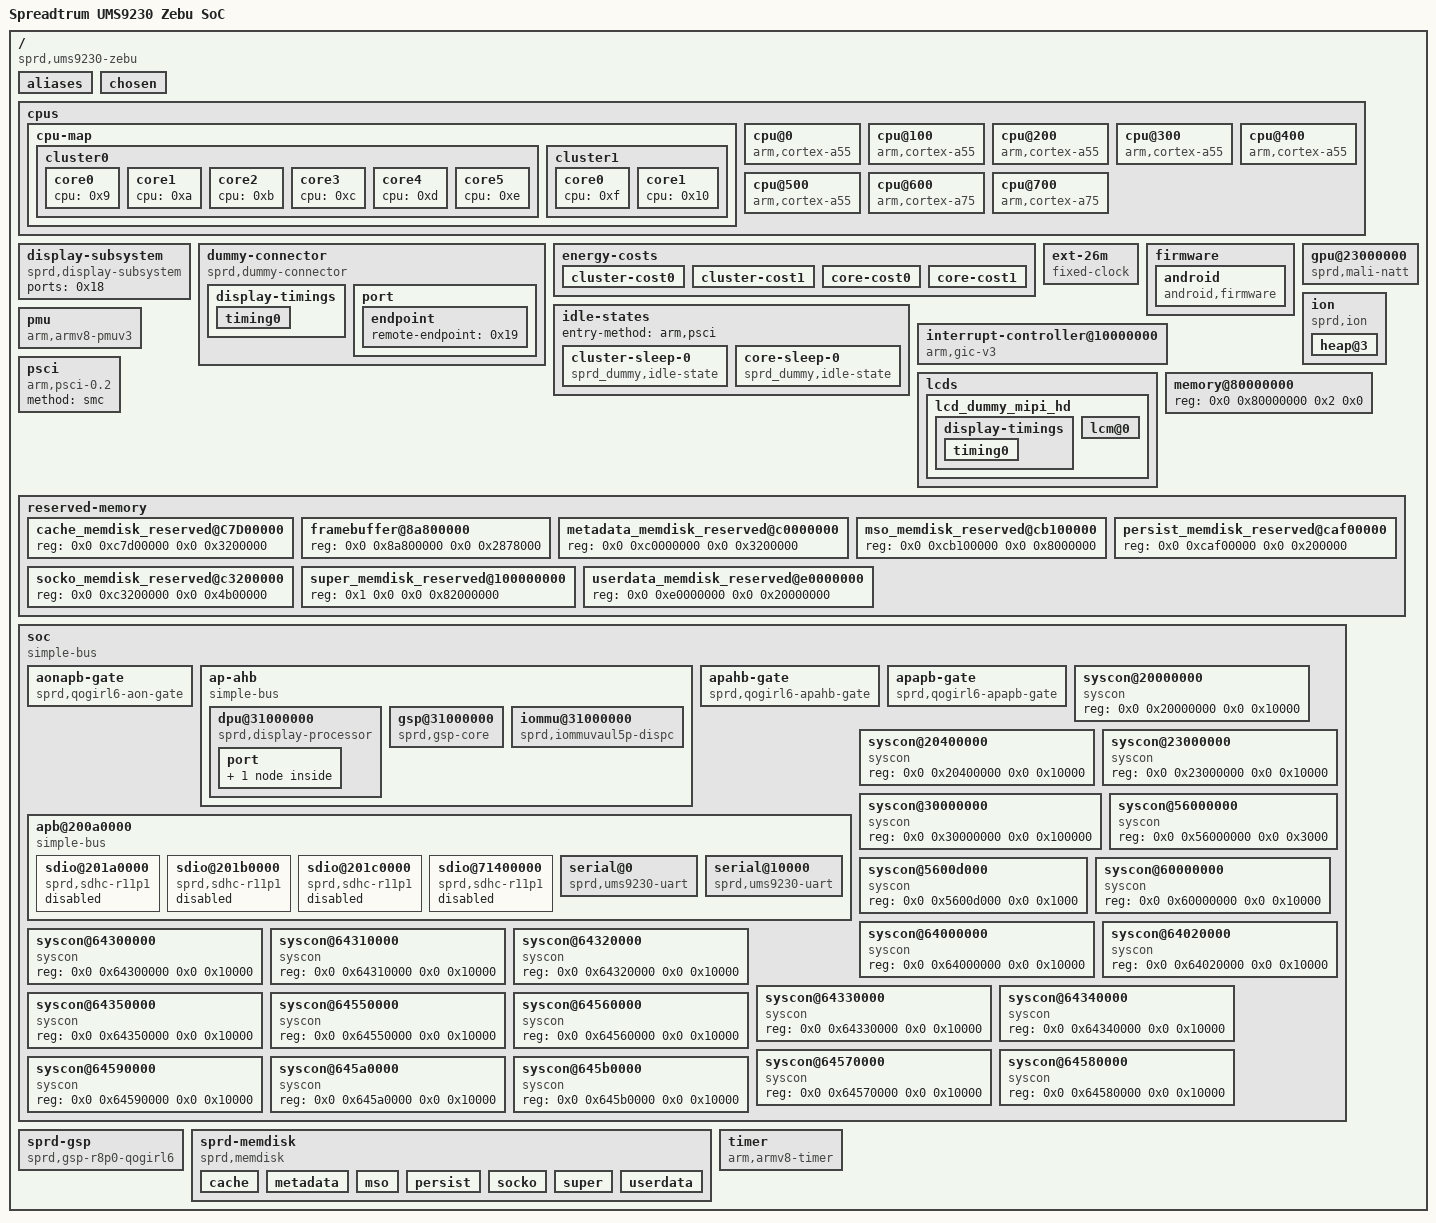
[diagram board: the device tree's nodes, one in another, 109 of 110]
/dts-v1/;

/ {
	#address-cells = <0x2>;
	#size-cells = <0x2>;
	compatible = "sprd,ums9230-zebu";
	interrupt-parent = <0x1>;
	model = "Spreadtrum UMS9230 Zebu SoC";
	sprd,sc-id = "ums9230-zebu 1000 1000";

	__symbols__ {
		CLUSTER_COST_0 = "/energy-costs/cluster-cost0";
		CLUSTER_COST_1 = "/energy-costs/cluster-cost1";
		CLUSTER_SLEEP_0 = "/idle-states/cluster-sleep-0";
		CORE_SLEEP_0 = "/idle-states/core-sleep-0";
		CPU0 = "/cpus/cpu@0";
		CPU1 = "/cpus/cpu@100";
		CPU2 = "/cpus/cpu@200";
		CPU3 = "/cpus/cpu@300";
		CPU4 = "/cpus/cpu@400";
		CPU5 = "/cpus/cpu@500";
		CPU6 = "/cpus/cpu@600";
		CPU7 = "/cpus/cpu@700";
		CPU_COST_0 = "/energy-costs/core-cost0";
		CPU_COST_1 = "/energy-costs/core-cost1";
		anlg_phy_g0_regs = "/soc/syscon@64550000";
		anlg_phy_g10_regs = "/soc/syscon@645b0000";
		anlg_phy_g1_regs = "/soc/syscon@64560000";
		anlg_phy_g2_regs = "/soc/syscon@64570000";
		anlg_phy_g3_regs = "/soc/syscon@64580000";
		anlg_phy_g4_regs = "/soc/syscon@64590000";
		anlg_phy_gc_regs = "/soc/syscon@645a0000";
		aon_apb_regs = "/soc/syscon@64000000";
		aonapb_gate = "/soc/aonapb-gate";
		ap_ahb_regs = "/soc/syscon@20400000";
		ap_apb_regs = "/soc/syscon@20000000";
		ap_intc0_regs = "/soc/syscon@64300000";
		ap_intc1_regs = "/soc/syscon@64310000";
		ap_intc2_regs = "/soc/syscon@64320000";
		ap_intc3_regs = "/soc/syscon@64330000";
		ap_intc4_regs = "/soc/syscon@64340000";
		ap_intc5_regs = "/soc/syscon@64350000";
		apahb_gate = "/soc/apahb-gate";
		apapb_gate = "/soc/apapb-gate";
		audcp_ahb_regs = "/soc/syscon@56000000";
		audcp_apb_regs = "/soc/syscon@5600d000";
		cache_memdisk_reserved = "/reserved-memory/cache_memdisk_reserved@C7D00000";
		chosen = "/chosen";
		dpu = "/soc/ap-ahb/dpu@31000000";
		dpu_out = "/soc/ap-ahb/dpu@31000000/port/endpoint";
		dpu_port = "/soc/ap-ahb/dpu@31000000/port";
		dummy_connector_in = "/dummy-connector/port/endpoint";
		ext_26m = "/ext-26m";
		fb_reserved = "/reserved-memory/framebuffer@8a800000";
		gic = "/interrupt-controller@10000000";
		gpu = "/gpu@23000000";
		gpu_apb_regs = "/soc/syscon@23000000";
		gsp = "/sprd-gsp";
		gsp_core0 = "/soc/ap-ahb/gsp@31000000";
		iommu_dispc = "/soc/ap-ahb/iommu@31000000";
		lcd_dummy_mipi_hd = "/lcds/lcd_dummy_mipi_hd";
		lcd_dummy_timing0 = "/lcds/lcd_dummy_mipi_hd/display-timings/timing0";
		metadata_memdisk_reserved = "/reserved-memory/metadata_memdisk_reserved@c0000000";
		mm_ahb_regs = "/soc/syscon@30000000";
		mso_memdisk_reserved = "/reserved-memory/mso_memdisk_reserved@cb100000";
		persist_memdisk_reserved = "/reserved-memory/persist_memdisk_reserved@caf00000";
		pmu_apb_regs = "/soc/syscon@64020000";
		pub_apb_regs = "/soc/syscon@60000000";
		sdio0 = "/soc/apb@200a0000/sdio@201a0000";
		sdio1 = "/soc/apb@200a0000/sdio@201b0000";
		sdio2 = "/soc/apb@200a0000/sdio@201c0000";
		sdio3 = "/soc/apb@200a0000/sdio@71400000";
		soc = "/soc";
		socko_memdisk_reserved = "/reserved-memory/socko_memdisk_reserved@c3200000";
		super_memdisk_reserved = "/reserved-memory/super_memdisk_reserved@100000000";
		uart0 = "/soc/apb@200a0000/serial@0";
		uart1 = "/soc/apb@200a0000/serial@10000";
		userdata_memdisk_reserved = "/reserved-memory/userdata_memdisk_reserved@e0000000";
	};

	aliases {
		serial0 = "/soc/apb@200a0000/serial@0";
		serial1 = "/soc/apb@200a0000/serial@10000";
	};

	chosen {
		bootargs = "earlycon console=ttyS0,26000000n8 loglevel=8 init=/init root=/dev/ram0 rw printk.devkmsg=on androidboot.selinux=permissive";
		phandle = <0x42>;
		stdout-path = "/soc/apb@200a0000/serial@0";
	};

	cpus {
		#address-cells = <0x2>;
		#size-cells = <0x0>;

		cpu-map {

			cluster0 {

				core0 {
					cpu = <0x9>;
				};

				core1 {
					cpu = <0xa>;
				};

				core2 {
					cpu = <0xb>;
				};

				core3 {
					cpu = <0xc>;
				};

				core4 {
					cpu = <0xd>;
				};

				core5 {
					cpu = <0xe>;
				};
			};

			cluster1 {

				core0 {
					cpu = <0xf>;
				};

				core1 {
					cpu = <0x10>;
				};
			};
		};

		cpu@0 {
			capacity-dmips-mhz = <0x220>;
			compatible = "arm,cortex-a55", "arm,armv8";
			cpu-idle-states = <0x11 0x12>;
			device_type = "cpu";
			enable-method = "psci";
			operating-points = <0x1bc560 0xf4240 0x1a2f20 0xe7ef0 0x177000 0xdbba0 0x169d10 0xcf850 0x12bce0 0xc3500 0x1174c0 0xb71b0 0xbb800 0xaae60>;
			phandle = <0x9>;
			reg = <0x0 0x0>;
			sched-energy-costs = <0x13 0x14>;
		};

		cpu@100 {
			capacity-dmips-mhz = <0x220>;
			compatible = "arm,cortex-a55", "arm,armv8";
			cpu-idle-states = <0x11 0x12>;
			device_type = "cpu";
			enable-method = "psci";
			phandle = <0xa>;
			reg = <0x0 0x100>;
			sched-energy-costs = <0x13 0x14>;
		};

		cpu@200 {
			capacity-dmips-mhz = <0x220>;
			compatible = "arm,cortex-a55", "arm,armv8";
			cpu-idle-states = <0x11 0x12>;
			device_type = "cpu";
			enable-method = "psci";
			phandle = <0xb>;
			reg = <0x0 0x200>;
			sched-energy-costs = <0x13 0x14>;
		};

		cpu@300 {
			capacity-dmips-mhz = <0x220>;
			compatible = "arm,cortex-a55", "arm,armv8";
			cpu-idle-states = <0x11 0x12>;
			device_type = "cpu";
			enable-method = "psci";
			phandle = <0xc>;
			reg = <0x0 0x300>;
			sched-energy-costs = <0x13 0x14>;
		};

		cpu@400 {
			capacity-dmips-mhz = <0x220>;
			compatible = "arm,cortex-a55", "arm,armv8";
			cpu-idle-states = <0x11 0x12>;
			device_type = "cpu";
			enable-method = "psci";
			phandle = <0xd>;
			reg = <0x0 0x400>;
			sched-energy-costs = <0x13 0x14>;
		};

		cpu@500 {
			capacity-dmips-mhz = <0x220>;
			compatible = "arm,cortex-a55", "arm,armv8";
			cpu-idle-states = <0x11 0x12>;
			device_type = "cpu";
			enable-method = "psci";
			phandle = <0xe>;
			reg = <0x0 0x500>;
			sched-energy-costs = <0x13 0x14>;
		};

		cpu@600 {
			capacity-dmips-mhz = <0x400>;
			compatible = "arm,cortex-a75", "arm,armv8";
			cpu-idle-states = <0x11 0x12>;
			device_type = "cpu";
			enable-method = "psci";
			operating-points = <0x1ef1e0 0xf4240 0x1c9080 0xe7ef0 0x1a94b0 0xdbba0 0x177000 0xcf850 0x169d10 0xc3500 0x12c0c8 0xb71b0>;
			phandle = <0xf>;
			reg = <0x0 0x600>;
			sched-energy-costs = <0x15 0x16>;
		};

		cpu@700 {
			capacity-dmips-mhz = <0x400>;
			compatible = "arm,cortex-a75", "arm,armv8";
			cpu-idle-states = <0x11 0x12>;
			device_type = "cpu";
			enable-method = "psci";
			phandle = <0x10>;
			reg = <0x0 0x700>;
			sched-energy-costs = <0x15 0x16>;
		};
	};

	display-subsystem {
		compatible = "sprd,display-subsystem";
		ports = <0x18>;
	};

	dummy-connector {
		compatible = "sprd,dummy-connector";

		display-timings {

			timing0 {
				clock-frequency = <0xb71b000>;
				hactive = <0x438>;
				hback-porch = <0x32>;
				hfront-porch = <0x32>;
				hsync-len = <0x2f>;
				vactive = <0x780>;
				vback-porch = <0x32>;
				vfront-porch = <0x32>;
				vsync-len = <0x2f>;
			};
		};

		port {

			endpoint {
				phandle = <0x4>;
				remote-endpoint = <0x19>;
			};
		};
	};

	energy-costs {

		cluster-cost0 {
			busy-cost-data = <0xce 0x0 0x133 0x0 0x149 0x0 0x18d 0x0 0x19c 0x0 0x1cc 0x0 0x1e8 0x0>;
			idle-cost-data = <0x0 0x0 0x0 0x0>;
			phandle = <0x14>;
		};

		cluster-cost1 {
			busy-cost-data = <0x26d 0x2d 0x2ec 0x3b 0x308 0x46 0x370 0x53 0x3b1 0x62 0x400 0x70>;
			idle-cost-data = <0xe 0xe 0xe 0x0>;
			phandle = <0x16>;
		};

		core-cost0 {
			busy-cost-data = <0xce 0x44 0x133 0x63 0x149 0x75 0x18d 0x96 0x19c 0xab 0x1cc 0xcf 0x1e8 0xf1>;
			idle-cost-data = <0x25 0x25 0x0 0x0>;
			phandle = <0x13>;
		};

		core-cost1 {
			busy-cost-data = <0x26d 0x19c 0x2ec 0x21b 0x308 0x26f 0x370 0x303 0x3b1 0x390 0x400 0x43b>;
			idle-cost-data = <0x74 0x74 0x0 0x0>;
			phandle = <0x15>;
		};
	};

	ext-26m {
		#clock-cells = <0x0>;
		clock-frequency = <0x18cba80>;
		clock-output-names = "ext-26m";
		compatible = "fixed-clock";
		phandle = <0x2>;
	};

	firmware {

		android {
			compatible = "android,firmware";
		};
	};

	gpu@23000000 {
		compatible = "sprd,mali-natt";
		interrupt-names = "JOB", "MMU", "GPU";
		interrupts = <0x0 0x3c 0x4 0x0 0x3c 0x4 0x0 0x3c 0x4>;
		operating-points = <0xcf850 0x0 0xbb800 0x0 0x7d000 0x0>;
		phandle = <0x43>;
		prd,dfs-scene-extreme = <0x2>;
		reg = <0x0 0x23100000 0x0 0x4000>;
		sprd,dfs-default = <0x2>;
		sprd,dfs-lists = <0x7d000 0x2 0x1 0xbb800 0x3 0x1 0xcf850 0x4 0x1>;
		sprd,dfs-range-max = <0x2>;
		sprd,dfs-range-min = <0x0>;
		sprd,dfs-scene-high = <0x1>;
		sprd,dfs-scene-low = <0x0>;
		sprd,dfs-scene-medium = <0x1>;
	};

	idle-states {
		entry-method = "arm,psci";

		cluster-sleep-0 {
			arm,psci-suspend-param = <0x1010000>;
			compatible = "sprd_dummy,idle-state";
			entry-latency-us = <0x258>;
			exit-latency-us = <0x3e8>;
			local-timer-stop;
			min-residency-us = <0xaf0>;
			phandle = <0x12>;
		};

		core-sleep-0 {
			arm,psci-suspend-param = <0x10000>;
			compatible = "sprd_dummy,idle-state";
			entry-latency-us = <0x190>;
			exit-latency-us = <0x258>;
			local-timer-stop;
			min-residency-us = <0x708>;
			phandle = <0x11>;
		};
	};

	interrupt-controller@10000000 {
		#address-cells = <0x2>;
		#interrupt-cells = <0x3>;
		#redistributor-regions = <0x1>;
		#size-cells = <0x2>;
		compatible = "arm,gic-v3";
		interrupt-controller;
		interrupts = <0x1 0x9 0x4>;
		phandle = <0x1>;
		ranges;
		redistributor-stride = <0x0 0x20000>;
		reg = <0x0 0x10000000 0x0 0x20000 0x0 0x10040000 0x0 0x100000>;
	};

	ion {
		#address-cells = <0x1>;
		#size-cells = <0x0>;
		compatible = "sprd,ion";

		heap@3 {
			label = "carveout_fb";
			memory-region = <0x17>;
			reg = <0x3>;
			type = <0x2>;
		};
	};

	lcds {

		lcd_dummy_mipi_hd {
			phandle = <0x40>;
			sleep-in = [13 0a 00 01 28 13 78 00 01 10];
			sleep-out = [13 78 00 01 11 13 64 00 01 29];
			sprd,lcd-id-tokernel = <0xffff>;
			sprd,lcd_buildin_name = "lcd_dummy_mipi_hd";

			display-timings {

				timing0 {
					clock-frequency = <0x493e000>;
					hback-porch = <0x3c>;
					hfront-porch = <0x50>;
					hsync-len = <0x3c>;
					phandle = <0x41>;
					sprd,phy-bit-clock = <0x9c400>;
					vback-porch = <0xc>;
					vfront-porch = <0x26>;
					vsync-len = <0x4>;
				};
			};

			lcm@0 {
				init-data = [13 78 00 01 11 13 64 00 01 29];
				lcm_ic_vendor = "dummy";
			};
		};
	};

	memory@80000000 {
		device_type = "memory";
		reg = <0x0 0x80000000 0x2 0x0>;
	};

	pmu {
		compatible = "arm,armv8-pmuv3";
		interrupts = <0x0 0x70 0x4 0x0 0x71 0x4 0x0 0x72 0x4 0x0 0x73 0x4 0x0 0x74 0x4 0x0 0x75 0x4 0x0 0x76 0x4 0x0 0x77 0x4>;
	};

	psci {
		compatible = "arm,psci-0.2";
		method = "smc";
	};

	reserved-memory {
		#address-cells = <0x2>;
		#size-cells = <0x2>;
		ranges;

		cache_memdisk_reserved@C7D00000 {
			phandle = <0x1e>;
			reg = <0x0 0xc7d00000 0x0 0x3200000>;
		};

		framebuffer@8a800000 {
			phandle = <0x17>;
			reg = <0x0 0x8a800000 0x0 0x2878000>;
		};

		metadata_memdisk_reserved@c0000000 {
			phandle = <0x1c>;
			reg = <0x0 0xc0000000 0x0 0x3200000>;
		};

		mso_memdisk_reserved@cb100000 {
			phandle = <0x20>;
			reg = <0x0 0xcb100000 0x0 0x8000000>;
		};

		persist_memdisk_reserved@caf00000 {
			phandle = <0x1f>;
			reg = <0x0 0xcaf00000 0x0 0x200000>;
		};

		socko_memdisk_reserved@c3200000 {
			phandle = <0x1d>;
			reg = <0x0 0xc3200000 0x0 0x4b00000>;
		};

		super_memdisk_reserved@100000000 {
			phandle = <0x1a>;
			reg = <0x1 0x0 0x0 0x82000000>;
		};

		userdata_memdisk_reserved@e0000000 {
			phandle = <0x1b>;
			reg = <0x0 0xe0000000 0x0 0x20000000>;
		};
	};

	soc {
		#address-cells = <0x2>;
		#size-cells = <0x2>;
		compatible = "simple-bus";
		phandle = <0x21>;
		ranges;

		aonapb-gate {
			#clock-cells = <0x1>;
			clocks = <0x2>;
			compatible = "sprd,qogirl6-aon-gate";
			phandle = <0x3d>;
			sprd,syscon = <0x6>;
		};

		ap-ahb {
			#address-cells = <0x2>;
			#size-cells = <0x2>;
			compatible = "simple-bus";
			ranges;

			dpu@31000000 {
				compatible = "sprd,display-processor";
				dma-coherent;
				interrupts = <0x0 0x1b 0x4>;
				iommus = <0x3>;
				phandle = <0x3b>;
				reg = <0x0 0x31000000 0x0 0x1000>;
				sprd,initial-stop-state;
				sprd,ip = "dpu-r5p0";
				sprd,soc = "qogirl6";
				status = "okay";
				syscon-names = "reset";

				port {
					phandle = <0x18>;

					endpoint {
						phandle = <0x19>;
						remote-endpoint = <0x4>;
					};
				};
			};

			gsp@31000000 {
				compatible = "sprd,gsp-core";
				core-id = <0x0>;
				interrupts = <0x0 0x1a 0x4>;
				iommus = <0x3>;
				kcfg-num = <0x10>;
				phandle = <0x8>;
				reg = <0x0 0x31000000 0x0 0x2000>;
			};

			iommu@31000000 {
				#iommu-cells = <0x0>;
				compatible = "sprd,iommuvaul5p-dispc";
				iova-base = <0x30000000>;
				iova-size = <0x10000000>;
				phandle = <0x3>;
				reg = <0x0 0x31000000 0x0 0x800 0x0 0x31000800 0x0 0x80>;
				reg_name = "mmu_interrupt_reg", "mmu_reg";
				status = "okay";
			};
		};

		apahb-gate {
			#clock-cells = <0x1>;
			clocks = <0x2>;
			compatible = "sprd,qogirl6-apahb-gate";
			phandle = <0x3c>;
			sprd,syscon = <0x5>;
		};

		apapb-gate {
			#clock-cells = <0x1>;
			clocks = <0x2>;
			compatible = "sprd,qogirl6-apapb-gate";
			phandle = <0x3e>;
			sprd,syscon = <0x7>;
		};

		apb@200a0000 {
			#address-cells = <0x1>;
			#size-cells = <0x1>;
			compatible = "simple-bus";
			ranges = <0x0 0x0 0x200a0000 0x10000000>;

			sdio@201a0000 {
				compatible = "sprd,sdhc-r11p1";
				interrupts = <0x0 0x13 0x4>;
				phandle = <0x38>;
				reg = <0x201a0000 0x1000>;
				status = "disabled";
			};

			sdio@201b0000 {
				compatible = "sprd,sdhc-r11p1";
				interrupts = <0x0 0x14 0x4>;
				phandle = <0x39>;
				reg = <0x201b0000 0x1000>;
				status = "disabled";
			};

			sdio@201c0000 {
				compatible = "sprd,sdhc-r11p1";
				interrupts = <0x0 0x15 0x4>;
				phandle = <0x3a>;
				reg = <0x201c0000 0x1000>;
				status = "disabled";
			};

			sdio@71400000 {
				compatible = "sprd,sdhc-r11p1";
				interrupts = <0x0 0xa 0x4>;
				phandle = <0x37>;
				reg = <0x71400000 0x1000>;
				status = "disabled";
			};

			serial@0 {
				clock-names = "enable", "uart", "source";
				clocks = <0x2>;
				compatible = "sprd,ums9230-uart", "sprd,sc9836-uart";
				interrupts = <0x0 0x2 0x4>;
				phandle = <0x35>;
				reg = <0x0 0x100>;
				sprd,keep-raw-clk;
				status = "okay";
			};

			serial@10000 {
				clock-names = "enable", "uart", "source";
				clocks = <0x2>;
				compatible = "sprd,ums9230-uart", "sprd,sc9836-uart";
				interrupts = <0x0 0x3 0x4>;
				phandle = <0x36>;
				reg = <0x10000 0x100>;
				sprd,keep-raw-clk;
				status = "okay";
			};
		};

		syscon@20000000 {
			#syscon-cells = <0x2>;
			compatible = "syscon";
			phandle = <0x7>;
			reg = <0x0 0x20000000 0x0 0x10000>;
		};

		syscon@20400000 {
			#syscon-cells = <0x2>;
			compatible = "syscon";
			phandle = <0x5>;
			reg = <0x0 0x20400000 0x0 0x10000>;
		};

		syscon@23000000 {
			#syscon-cells = <0x2>;
			compatible = "syscon";
			phandle = <0x22>;
			reg = <0x0 0x23000000 0x0 0x10000>;
		};

		syscon@30000000 {
			#syscon-cells = <0x2>;
			compatible = "syscon";
			phandle = <0x23>;
			reg = <0x0 0x30000000 0x0 0x100000>;
		};

		syscon@56000000 {
			#syscon-cells = <0x2>;
			compatible = "syscon";
			phandle = <0x24>;
			reg = <0x0 0x56000000 0x0 0x3000>;
		};

		syscon@5600d000 {
			#syscon-cells = <0x2>;
			compatible = "syscon";
			phandle = <0x25>;
			reg = <0x0 0x5600d000 0x0 0x1000>;
		};

		syscon@60000000 {
			#syscon-cells = <0x2>;
			compatible = "syscon";
			phandle = <0x26>;
			reg = <0x0 0x60000000 0x0 0x10000>;
		};

		syscon@64000000 {
			#syscon-cells = <0x2>;
			compatible = "syscon";
			phandle = <0x6>;
			reg = <0x0 0x64000000 0x0 0x10000>;
		};

		syscon@64020000 {
			#syscon-cells = <0x2>;
			compatible = "syscon";
			phandle = <0x27>;
			reg = <0x0 0x64020000 0x0 0x10000>;
		};

		syscon@64300000 {
			#syscon-cells = <0x2>;
			compatible = "syscon";
			phandle = <0x28>;
			reg = <0x0 0x64300000 0x0 0x10000>;
		};

		syscon@64310000 {
			#syscon-cells = <0x2>;
			compatible = "syscon";
			phandle = <0x29>;
			reg = <0x0 0x64310000 0x0 0x10000>;
		};

		syscon@64320000 {
			#syscon-cells = <0x2>;
			compatible = "syscon";
			phandle = <0x2a>;
			reg = <0x0 0x64320000 0x0 0x10000>;
		};

		syscon@64330000 {
			#syscon-cells = <0x2>;
			compatible = "syscon";
			phandle = <0x2b>;
			reg = <0x0 0x64330000 0x0 0x10000>;
		};

		syscon@64340000 {
			#syscon-cells = <0x2>;
			compatible = "syscon";
			phandle = <0x2c>;
			reg = <0x0 0x64340000 0x0 0x10000>;
		};

		syscon@64350000 {
			#syscon-cells = <0x2>;
			compatible = "syscon";
			phandle = <0x2d>;
			reg = <0x0 0x64350000 0x0 0x10000>;
		};

		syscon@64550000 {
			#syscon-cells = <0x2>;
			compatible = "syscon";
			phandle = <0x2e>;
			reg = <0x0 0x64550000 0x0 0x10000>;
		};

		syscon@64560000 {
			#syscon-cells = <0x2>;
			compatible = "syscon";
			phandle = <0x2f>;
			reg = <0x0 0x64560000 0x0 0x10000>;
		};

		syscon@64570000 {
			#syscon-cells = <0x2>;
			compatible = "syscon";
			phandle = <0x30>;
			reg = <0x0 0x64570000 0x0 0x10000>;
		};

		syscon@64580000 {
			#syscon-cells = <0x2>;
			compatible = "syscon";
			phandle = <0x31>;
			reg = <0x0 0x64580000 0x0 0x10000>;
		};

		syscon@64590000 {
			#syscon-cells = <0x2>;
			compatible = "syscon";
			phandle = <0x32>;
			reg = <0x0 0x64590000 0x0 0x10000>;
		};

		syscon@645a0000 {
			#syscon-cells = <0x2>;
			compatible = "syscon";
			phandle = <0x33>;
			reg = <0x0 0x645a0000 0x0 0x10000>;
		};

		syscon@645b0000 {
			#syscon-cells = <0x2>;
			compatible = "syscon";
			phandle = <0x34>;
			reg = <0x0 0x645b0000 0x0 0x10000>;
		};
	};

	sprd-gsp {
		compatible = "sprd,gsp-r8p0-qogirl6";
		core-cnt = <0x1>;
		cores = <0x8>;
		io-cnt = <0x7>;
		phandle = <0x3f>;
	};

	sprd-memdisk {
		compatible = "sprd,memdisk";

		cache {
			label = "cache";
			memory-region = <0x1e>;
		};

		metadata {
			label = "metadata";
			memory-region = <0x1c>;
		};

		mso {
			label = "mso";
			memory-region = <0x20>;
		};

		persist {
			label = "persist";
			memory-region = <0x1f>;
		};

		socko {
			label = "socko";
			memory-region = <0x1d>;
		};

		super {
			label = "super";
			memory-region = <0x1a>;
		};

		userdata {
			label = "userdata";
			memory-region = <0x1b>;
		};
	};

	timer {
		arm,no-tick-in-suspend;
		compatible = "arm,armv8-timer";
		interrupts = <0x1 0xd 0x4 0x1 0xe 0x4 0x1 0xb 0x4 0x1 0xa 0x4>;
	};
};
